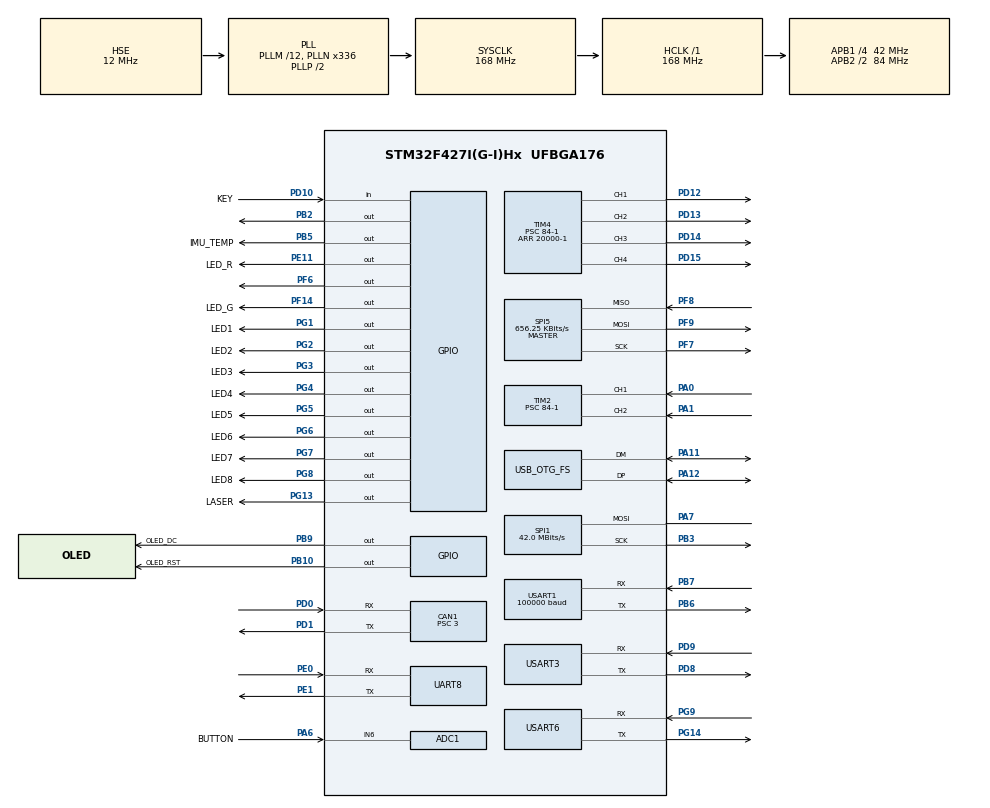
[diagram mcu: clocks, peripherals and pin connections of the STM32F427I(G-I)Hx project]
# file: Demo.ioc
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ADC1.Channel-1\#ChannelRegularConversion=ADC_CHANNEL_6
ADC1.ContinuousConvMode=ENABLE
ADC1.DMAContinuousRequests=ENABLE
ADC1.NbrOfConversionFlag=1
ADC1.Rank-1\#ChannelRegularConversion=1
ADC1.SamplingTime-1\#ChannelRegularConversion=ADC_SAMPLETIME_3CYCLES
ADC1.ScanConvMode=ENABLE
ADC1.master=1
CAN1.ABOM=ENABLE
CAN1.BS1=CAN_BS1_9TQ
CAN1.BS2=CAN_BS2_4TQ
CAN1.CalculateTimeQuantum=71.42857142857143
CAN1.Prescaler=3
Dma.ADC1.1.Direction=DMA_PERIPH_TO_MEMORY
Dma.ADC1.1.FIFOMode=DMA_FIFOMODE_DISABLE
Dma.ADC1.1.Instance=DMA2_Stream0
Dma.ADC1.1.MemDataAlignment=DMA_MDATAALIGN_WORD
Dma.ADC1.1.MemInc=DMA_MINC_ENABLE
Dma.ADC1.1.Mode=DMA_CIRCULAR
Dma.ADC1.1.PeriphDataAlignment=DMA_PDATAALIGN_WORD
Dma.ADC1.1.PeriphInc=DMA_PINC_DISABLE
Dma.ADC1.1.Priority=DMA_PRIORITY_LOW
Dma.Request0=USART1_RX
Dma.Request1=ADC1
Dma.Request2=USART6_RX
Dma.Request3=USART6_TX
Dma.USART1_RX.0.Direction=DMA_PERIPH_TO_MEMORY
Dma.USART1_RX.0.FIFOMode=DMA_FIFOMODE_DISABLE
Dma.USART1_RX.0.Instance=DMA2_Stream2
Dma.USART1_RX.0.MemDataAlignment=DMA_MDATAALIGN_BYTE
Dma.USART1_RX.0.MemInc=DMA_MINC_ENABLE
Dma.USART1_RX.0.Mode=DMA_NORMAL
Dma.USART1_RX.0.PeriphDataAlignment=DMA_PDATAALIGN_BYTE
Dma.USART1_RX.0.PeriphInc=DMA_PINC_DISABLE
Dma.USART1_RX.0.Priority=DMA_PRIORITY_LOW
Dma.USART6_RX.2.Direction=DMA_PERIPH_TO_MEMORY
Dma.USART6_RX.2.FIFOMode=DMA_FIFOMODE_DISABLE
Dma.USART6_RX.2.Instance=DMA2_Stream1
Dma.USART6_RX.2.MemDataAlignment=DMA_MDATAALIGN_BYTE
Dma.USART6_RX.2.MemInc=DMA_MINC_ENABLE
Dma.USART6_RX.2.Mode=DMA_NORMAL
Dma.USART6_RX.2.PeriphDataAlignment=DMA_PDATAALIGN_BYTE
Dma.USART6_RX.2.PeriphInc=DMA_PINC_DISABLE
Dma.USART6_RX.2.Priority=DMA_PRIORITY_LOW
Dma.USART6_TX.3.Direction=DMA_MEMORY_TO_PERIPH
Dma.USART6_TX.3.FIFOMode=DMA_FIFOMODE_DISABLE
Dma.USART6_TX.3.Instance=DMA2_Stream6
Dma.USART6_TX.3.MemDataAlignment=DMA_MDATAALIGN_BYTE
Dma.USART6_TX.3.MemInc=DMA_MINC_ENABLE
Dma.USART6_TX.3.Mode=DMA_NORMAL
Dma.USART6_TX.3.PeriphDataAlignment=DMA_PDATAALIGN_BYTE
Dma.USART6_TX.3.PeriphInc=DMA_PINC_DISABLE
Dma.USART6_TX.3.Priority=DMA_PRIORITY_LOW
FREERTOS.Tasks01=Task_WWDG,3,128,StartTask_WWDG,Default,NULL,Dynamic,NULL,NULL
Mcu.Family=STM32F4
Mcu.Name=STM32F427I(G-I)Hx
Mcu.Package=UFBGA176
NVIC.CAN1_RX0_IRQn=true\:5\:0\:false\:false\:true\:true\:true\:true
NVIC.CAN1_TX_IRQn=true\:5\:0\:false\:false\:true\:true\:true\:true
NVIC.DMA2_Stream0_IRQn=true\:5\:0\:false\:false\:true\:true\:false\:true
NVIC.DMA2_Stream1_IRQn=true\:5\:0\:false\:false\:true\:true\:false\:true
NVIC.DMA2_Stream2_IRQn=true\:5\:0\:false\:false\:true\:true\:false\:true
NVIC.DMA2_Stream6_IRQn=true\:5\:0\:false\:false\:true\:true\:false\:true
NVIC.OTG_FS_IRQn=true\:5\:0\:false\:false\:true\:true\:true\:true
NVIC.PriorityGroup=NVIC_PRIORITYGROUP_4
NVIC.TIM1_UP_TIM10_IRQn=true\:0\:0\:false\:false\:true\:false\:false\:true
NVIC.TIM2_IRQn=true\:5\:0\:false\:false\:true\:true\:true\:true
NVIC.TimeBase=TIM1_UP_TIM10_IRQn
NVIC.TimeBaseIP=TIM1
NVIC.USART1_IRQn=true\:5\:0\:false\:false\:true\:true\:true\:true
PA0/WKUP.GPIO_ModeDefaultPP=GPIO_MODE_AF_PP
PA0/WKUP.GPIO_PuPd=GPIO_PULLDOWN
PA0/WKUP.GPIO_Speed=GPIO_SPEED_FREQ_VERY_HIGH
PA0/WKUP.Signal=S_TIM2_CH1_ETR
PA1.GPIO_PuPd=GPIO_PULLDOWN
PA1.GPIO_Speed=GPIO_SPEED_FREQ_VERY_HIGH
PA1.Signal=S_TIM2_CH2
PA11.Mode=Device_Only
PA11.Signal=USB_OTG_FS_DM
PA12.Mode=Device_Only
PA12.Signal=USB_OTG_FS_DP
PA6.GPIO_Label=BUTTON
PA6.Signal=ADCx_IN6
PA7.Mode=Simplex_Bidirectional_Master
PA7.Signal=SPI1_MOSI
PB10.GPIO_Label=OLED_RST
PB10.Signal=GPIO_Output
PB2/BOOT1.Signal=GPIO_Output
PB3.Mode=Simplex_Bidirectional_Master
PB3.Signal=SPI1_SCK
PB5.GPIO_Label=IMU_TEMP
PB5.Signal=GPIO_Output
PB6.Mode=Asynchronous
PB6.Signal=USART1_TX
PB7.Mode=Asynchronous
PB7.Signal=USART1_RX
PB9.GPIO_Label=OLED_DC
PB9.Signal=GPIO_Output
PD0.Mode=Master
PD0.Signal=CAN1_RX
PD1.Mode=Master
PD1.Signal=CAN1_TX
PD10.GPIO_Label=KEY
PD10.Signal=GPIO_Input
PD12.Signal=S_TIM4_CH1
PD13.Signal=S_TIM4_CH2
PD14.Signal=S_TIM4_CH3
PD15.Signal=S_TIM4_CH4
PD8.Mode=Asynchronous
PD8.Signal=USART3_TX
PD9.Mode=Asynchronous
PD9.Signal=USART3_RX
PE0.Mode=Asynchronous
PE0.Signal=UART8_RX
PE1.Mode=Asynchronous
PE1.Signal=UART8_TX
PE11.GPIO_Label=LED_R
PE11.Signal=GPIO_Output
PF14.GPIO_Label=LED_G
PF14.Signal=GPIO_Output
PF6.Signal=GPIO_Output
PF7.Mode=Full_Duplex_Master
PF7.Signal=SPI5_SCK
PF8.Mode=Full_Duplex_Master
PF8.Signal=SPI5_MISO
PF9.Mode=Full_Duplex_Master
PF9.Signal=SPI5_MOSI
PG1.GPIO_Label=LED1
PG1.Signal=GPIO_Output
PG13.GPIO_Label=LASER
PG13.PinState=GPIO_PIN_SET
PG13.Signal=GPIO_Output
PG14.Mode=Asynchronous
PG14.Signal=USART6_TX
PG2.GPIO_Label=LED2
PG2.Signal=GPIO_Output
PG3.GPIO_Label=LED3
PG3.Signal=GPIO_Output
PG4.GPIO_Label=LED4
PG4.Signal=GPIO_Output
PG5.GPIO_Label=LED5
PG5.Signal=GPIO_Output
PG6.GPIO_Label=LED6
PG6.Signal=GPIO_Output
PG7.GPIO_Label=LED7
PG7.Signal=GPIO_Output
PG8.GPIO_Label=LED8
PG8.Signal=GPIO_Output
PG9.Mode=Asynchronous
PG9.Signal=USART6_RX
PH0/OSC_IN.Mode=HSE-External-Oscillator
PH0/OSC_IN.Signal=RCC_OSC_IN
PH1/OSC_OUT.Mode=HSE-External-Oscillator
PH1/OSC_OUT.Signal=RCC_OSC_OUT
PH6.GPIO_Label=Buzzer
PH6.Signal=S_TIM12_CH1
ProjectManager.HeapSize=0x2000
ProjectManager.StackSize=0x4000
ProjectManager.TargetToolchain=MDK-ARM V5
RCC.48MHZClocksFreq_Value=48000000
RCC.AHBFreq_Value=168000000
RCC.APB1CLKDivider=RCC_HCLK_DIV4
RCC.APB1Freq_Value=42000000
RCC.APB1TimFreq_Value=84000000
RCC.APB2CLKDivider=RCC_HCLK_DIV2
RCC.APB2Freq_Value=84000000
RCC.APB2TimFreq_Value=168000000
RCC.CortexFreq_Value=168000000
RCC.HCLKFreq_Value=168000000
RCC.HSE_VALUE=12000000
RCC.HSI_VALUE=16000000
RCC.LSE_VALUE=32768
RCC.PLLM=12
RCC.PLLN=336
RCC.PLLQ=7
RCC.SYSCLKFreq_VALUE=168000000
RCC.SYSCLKSource=RCC_SYSCLKSOURCE_PLLCLK
RCC.VCOOutputFreq_Value=336000000
SH.ADCx_IN6.0=ADC1_IN6,IN6
SH.S_TIM12_CH1.0=TIM12_CH1
SH.S_TIM2_CH1_ETR.0=TIM2_CH1,Input_Capture1_from_TI1
SH.S_TIM2_CH2.0=TIM2_CH2,Input_Capture2_from_TI2
SH.S_TIM4_CH1.0=TIM4_CH1,PWM Generation1 CH1
SH.S_TIM4_CH2.0=TIM4_CH2,PWM Generation2 CH2
SH.S_TIM4_CH3.0=TIM4_CH3,PWM Generation3 CH3
SH.S_TIM4_CH4.0=TIM4_CH4,PWM Generation4 CH4
SPI1.BaudRatePrescaler=SPI_BAUDRATEPRESCALER_2
SPI1.CalculateBaudRate=42.0 MBits/s
SPI1.Direction=SPI_DIRECTION_1LINE
SPI1.Mode=SPI_MODE_MASTER
SPI1.VirtualType=VM_MASTER
SPI5.BaudRatePrescaler=SPI_BAUDRATEPRESCALER_128
SPI5.CalculateBaudRate=656.25 KBits/s
SPI5.Direction=SPI_DIRECTION_2LINES
SPI5.Mode=SPI_MODE_MASTER
SPI5.VirtualType=VM_MASTER
TIM2.Channel-Input_Capture1_from_TI1=TIM_CHANNEL_1
TIM2.Channel-Input_Capture2_from_TI2=TIM_CHANNEL_2
TIM2.Period=65536-1
TIM2.Prescaler=84-1
TIM2.TIM_MasterOutputTrigger=TIM_TRGO_UPDATE
TIM4.Channel-PWM\ Generation1\ CH1=TIM_CHANNEL_1
TIM4.Channel-PWM\ Generation2\ CH2=TIM_CHANNEL_2
TIM4.Channel-PWM\ Generation3\ CH3=TIM_CHANNEL_3
TIM4.Channel-PWM\ Generation4\ CH4=TIM_CHANNEL_4
TIM4.ClockDivision=TIM_CLOCKDIVISION_DIV1
TIM4.Period=20000-1
TIM4.Prescaler=84-1
UART8.VirtualMode=Asynchronous
USART1.BaudRate=100000
USART1.VirtualMode=VM_ASYNC
USART3.VirtualMode=VM_ASYNC
USART6.VirtualMode=VM_ASYNC
USB_DEVICE.CLASS_NAME_FS=CDC
USB_DEVICE.VirtualMode-CDC_FS=Cdc
USB_DEVICE.VirtualModeFS=Cdc_FS
USB_OTG_FS.VirtualMode=Device_Only
VP_FREERTOS_VS_CMSIS_V1.Mode=CMSIS_V1
VP_SYS_VS_tim1.Mode=TIM1
VP_TIM2_VS_ClockSourceINT.Mode=Internal
VP_TIM4_VS_ClockSourceINT.Mode=Internal
VP_USB_DEVICE_VS_USB_DEVICE_CDC_FS.Mode=CDC_FS
board=custom

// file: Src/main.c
/* USER CODE BEGIN Header */
/**
  ******************************************************************************
  * @file           : main.c
  * @brief          : Main program body
  ******************************************************************************
  * @attention
  *
  * <h2><center>&copy; Copyright (c) 2019 STMicroelectronics.
  * All rights reserved.</center></h2>
  *
  * This software component is licensed by ST under BSD 3-Clause license,
  * the "License"; You may not use this file except in compliance with the
  * License. You may obtain a copy of the License at:
  *                        opensource.org/licenses/BSD-3-Clause
  *
  ******************************************************************************
  */
/* USER CODE END Header */

#include "main.h"
#include "cmsis_os.h"
#include "adc.h"
#include "can.h"
#include "dma.h"
#include "spi.h"
#include "tim.h"
#include "usart.h"
#include "usb_device.h"
#include "gpio.h"

/* USER CODE BEGIN Includes */
#include "task_tatal.h"

/* USER CODE END Includes */

/* USER CODE BEGIN PV */

uint8_t KEY_Value = 0 ;
//extern moto_info_t motor_info[MOTOR_MAX_NUM];
//pid_struct_t motor_pid[7];

/* USER CODE END PV */

void SystemClock_Config(void);
void MX_FREERTOS_Init(void);

int main(void)
{

  /* MCU Configuration--------------------------------------------------------*/

  /* Reset of all peripherals, Initializes the Flash interface and the Systick. */
  HAL_Init();

  /* Configure the system clock */
  SystemClock_Config();

  /* Initialize all configured peripherals */
  MX_GPIO_Init();
  MX_DMA_Init();
  MX_UART8_Init();
  MX_USART3_UART_Init();
  MX_USART6_UART_Init();
  MX_ADC1_Init();
  MX_SPI1_Init();
  MX_USART1_UART_Init();
  MX_CAN1_Init();
  MX_SPI5_Init();
  MX_TIM2_Init();
  MX_TIM4_Init();
  /* USER CODE BEGIN 2 */

  User_Init();               //用户应用函数初始化
	                                          //完成初始化后稳定状态

	Task_Init();                                  //初始化任务调度函数

  /* USER CODE END 2 */

  /* Call init function for freertos objects (in freertos.c) */
  MX_FREERTOS_Init();

  /* Start scheduler */
  osKernelStart();

  /* We should never get here as control is now taken by the scheduler */

  /* Infinite loop */
  while (1)
  {

  }
}

void SystemClock_Config(void)
{
  RCC_OscInitTypeDef RCC_OscInitStruct = {0};
  RCC_ClkInitTypeDef RCC_ClkInitStruct = {0};

  /** Configure the main internal regulator output voltage
  */
  __HAL_RCC_PWR_CLK_ENABLE();
  __HAL_PWR_VOLTAGESCALING_CONFIG(PWR_REGULATOR_VOLTAGE_SCALE1);
  /** Initializes the CPU, AHB and APB busses clocks
  */
  RCC_OscInitStruct.OscillatorType = RCC_OSCILLATORTYPE_HSE;
  RCC_OscInitStruct.HSEState = RCC_HSE_ON;
  RCC_OscInitStruct.PLL.PLLState = RCC_PLL_ON;
  RCC_OscInitStruct.PLL.PLLSource = RCC_PLLSOURCE_HSE;
  RCC_OscInitStruct.PLL.PLLM = 12;
  RCC_OscInitStruct.PLL.PLLN = 336;
  RCC_OscInitStruct.PLL.PLLP = RCC_PLLP_DIV2;
  RCC_OscInitStruct.PLL.PLLQ = 7;
  if (HAL_RCC_OscConfig(&RCC_OscInitStruct) != HAL_OK)
  {
    Error_Handler();
  }
  /** Initializes the CPU, AHB and APB busses clocks
  */
  RCC_ClkInitStruct.ClockType = RCC_CLOCKTYPE_HCLK|RCC_CLOCKTYPE_SYSCLK
                              |RCC_CLOCKTYPE_PCLK1|RCC_CLOCKTYPE_PCLK2;
  RCC_ClkInitStruct.SYSCLKSource = RCC_SYSCLKSOURCE_PLLCLK;
  RCC_ClkInitStruct.AHBCLKDivider = RCC_SYSCLK_DIV1;
  RCC_ClkInitStruct.APB1CLKDivider = RCC_HCLK_DIV4;
  RCC_ClkInitStruct.APB2CLKDivider = RCC_HCLK_DIV2;

  if (HAL_RCC_ClockConfig(&RCC_ClkInitStruct, FLASH_LATENCY_5) != HAL_OK)
  {
    Error_Handler();
  }
}

void HAL_TIM_PeriodElapsedCallback(TIM_HandleTypeDef *htim)
{
  if (htim->Instance == TIM1) {
    HAL_IncTick();
  }
  /* USER CODE BEGIN Callback 1 */
//if (htim->Instance == TIM2)
//	{
//
//  }

  /* USER CODE END Callback 1 */
}

void Error_Handler(void)
{
}

/************************ (C) COPYRIGHT STMicroelectronics *****END OF FILE****/

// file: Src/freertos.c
/* USER CODE BEGIN Header */
/**
  ******************************************************************************
  * File Name          : freertos.c
  * Description        : Code for freertos applications
  ******************************************************************************
  * @attention
  *
  * <h2><center>&copy; Copyright (c) 2019 STMicroelectronics.
  * All rights reserved.</center></h2>
  *
  * This software component is licensed by ST under Ultimate Liberty license
  * SLA0044, the "License"; You may not use this file except in compliance with
  * the License. You may obtain a copy of the License at:
  *                             www.st.com/SLA0044
  *
  ******************************************************************************
  */
/* USER CODE END Header */

#include "FreeRTOS.h"
#include "task.h"
#include "main.h"
#include "cmsis_os.h"

osThreadId Task_WWDGHandle;

void StartTask_WWDG(void const * argument);

extern void MX_USB_DEVICE_Init(void);
void MX_FREERTOS_Init(void); /* (MISRA C 2004 rule 8.1) */

/* GetIdleTaskMemory prototype (linked to static allocation support) */
void vApplicationGetIdleTaskMemory( StaticTask_t **ppxIdleTaskTCBBuffer, StackType_t **ppxIdleTaskStackBuffer, uint32_t *pulIdleTaskStackSize );

/* USER CODE BEGIN GET_IDLE_TASK_MEMORY */
static StaticTask_t xIdleTaskTCBBuffer;
static StackType_t xIdleStack[configMINIMAL_STACK_SIZE];

void vApplicationGetIdleTaskMemory( StaticTask_t **ppxIdleTaskTCBBuffer, StackType_t **ppxIdleTaskStackBuffer, uint32_t *pulIdleTaskStackSize )
{
  *ppxIdleTaskTCBBuffer = &xIdleTaskTCBBuffer;
  *ppxIdleTaskStackBuffer = &xIdleStack[0];
  *pulIdleTaskStackSize = configMINIMAL_STACK_SIZE;
  /* place for user code */
}
/* USER CODE END GET_IDLE_TASK_MEMORY */

void MX_FREERTOS_Init(void) {

  /* Create the thread(s) */
  /* definition and creation of Task_WWDG */
  osThreadDef(Task_WWDG, StartTask_WWDG, osPriorityRealtime, 0, 128);
  Task_WWDGHandle = osThreadCreate(osThread(Task_WWDG), NULL);

}

void StartTask_WWDG(void const * argument)
{

  /* init code for USB_DEVICE */
  MX_USB_DEVICE_Init();

  /* USER CODE BEGIN StartTask_WWDG */
	vTaskDelete( Task_WWDGHandle );
  /* Infinite loop */
  for(;;)
  {
    HAL_GPIO_TogglePin( GPIOG , LED3_Pin );
  }
  /* USER CODE END StartTask_WWDG */
}

/************************ (C) COPYRIGHT STMicroelectronics *****END OF FILE****/
